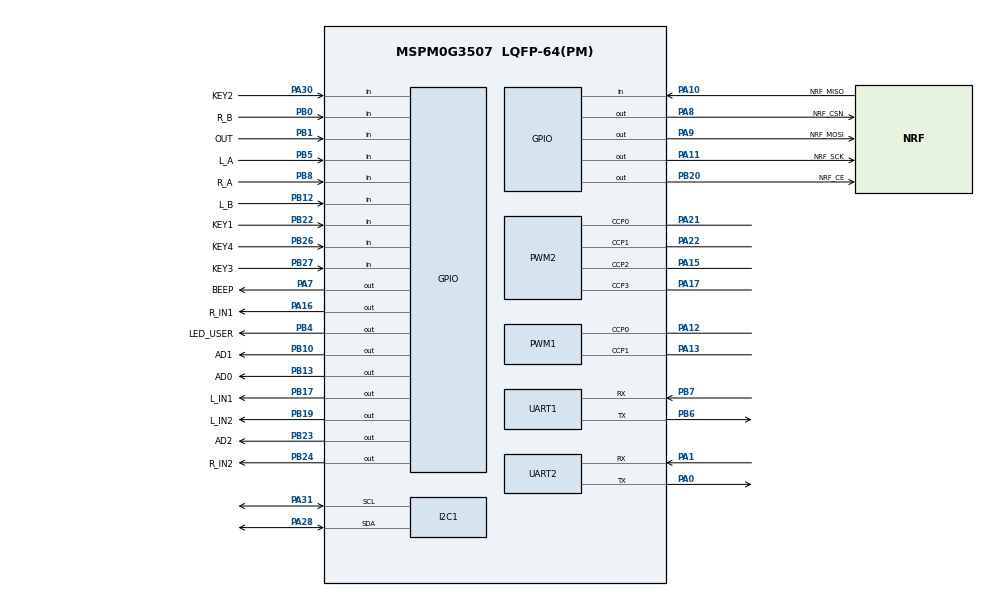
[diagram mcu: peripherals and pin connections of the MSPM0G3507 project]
/**
 * Revised local SysConfig script for the MSPM0G3507 slave car.
 *
 * MOTOR MIGRATION (2026-07): DC + TB6612 → Stepper + D36A.
 * - TB6612 L_IN1/L_IN2/R_IN1/R_IN2 GPIOs RETAINED as legacy output.
 *   PB17/PB19/PA16/PB24 are no longer used for DIR/EN.
 * - TIMG0 PWM_MOTOR PA12/PA13 RETAINED but unused at runtime.
 *
 * Stepper pins (initialized manually in StepperMotor.c):
 *   STEP_L = PB15 (TIMG7 CCP0, IOMUX_PINCM32 func6)
 *   STEP_R = PB16 (TIMG8 CCP1, IOMUX_PINCM33 func5)
 *   DIR_L  = PB18 (GPIO output, IOMUX_PINCM44)
 *   DIR_R  = PB25 (GPIO output, IOMUX_PINCM56)
 *   EN1/EN2 = hardware always enabled, no MCU GPIO.
 *
 * Encoder pins (initialized in Encoder.c):
 *   ENC_L_A = PB05 (IOMUX_PINCM18), ENC_L_B = PB12 (IOMUX_PINCM29)
 *   ENC_R_A = PB08 (IOMUX_PINCM25), ENC_R_B = PB00 (IOMUX_PINCM12)
 *   All on GPIOB, RISE_FALL interrupts, 4x quadrature.
 *
 * PB08 conflict: also H8 OLED SDA.  Set BOARD_OLED_USE_H8_I2C=0,
 * ECAR_OLED_ENABLE=0 when using stepper encoder.
 *
 * This file mirrors the checked-in ti_msp_dl_config.c/h logical names.
 * If SysConfig regenerates, keep App/Hardware code mapped through
 * Hardware/Board_Config.h.
 */
//@cliArgs --device "MSPM0G350X" --package "LQFP-64(PM)" --part "Default"
//@v2CliArgs --device "MSPM0G3507" --package "LQFP-64(PM)"
// @cliArgs --board /ti/boards/LP_MSPM0G3507 --rtos nortos

const GPIO   = scripting.addModule("/ti/driverlib/GPIO", {}, false);
const GPIO1  = GPIO.addInstance();
const GPIO2  = GPIO.addInstance();
const GPIO3  = GPIO.addInstance();
const GPIO4  = GPIO.addInstance();
const GPIO5  = GPIO.addInstance();
const GPIO_NRF = GPIO.addInstance();
const I2C    = scripting.addModule("/ti/driverlib/I2C", {}, false);
const I2C1   = I2C.addInstance();
const PWM    = scripting.addModule("/ti/driverlib/PWM", {}, false);
const PWM1   = PWM.addInstance();
const PWM2   = PWM.addInstance();
const TIMER  = scripting.addModule("/ti/driverlib/TIMER", {}, false);
const TIMER1 = TIMER.addInstance();
const UART   = scripting.addModule("/ti/driverlib/UART", {}, false);
const UART1  = UART.addInstance();
const SYSCTL = scripting.addModule("/ti/driverlib/SYSCTL");

const Board = scripting.addModule("/ti/driverlib/Board", {}, false);

/*
 * TB6612 motor GPIO (legacy, retained to keep SYSCFG_DL_GPIO_init stable):
 * L_IN1=PB17, L_IN2=PB19, R_IN1=PA16, R_IN2=PB24.
 * Not used in stepper mode.
 */
GPIO1.$name = "GPIO_MOTOR";
GPIO1.associatedPins.create(4);
GPIO1.associatedPins[0].$name        = "L_IN1";
GPIO1.associatedPins[0].assignedPort = "PORTB";
GPIO1.associatedPins[0].assignedPin  = "17";
GPIO1.associatedPins[0].pin.$assign  = "PB17";
GPIO1.associatedPins[0].initialValue = "CLEARED";
GPIO1.associatedPins[1].$name        = "L_IN2";
GPIO1.associatedPins[1].assignedPort = "PORTB";
GPIO1.associatedPins[1].assignedPin  = "19";
GPIO1.associatedPins[1].pin.$assign  = "PB19";
GPIO1.associatedPins[1].initialValue = "CLEARED";
GPIO1.associatedPins[2].$name        = "R_IN1";
GPIO1.associatedPins[2].assignedPort = "PORTA";
GPIO1.associatedPins[2].assignedPin  = "16";
GPIO1.associatedPins[2].pin.$assign  = "PA16";
GPIO1.associatedPins[2].initialValue = "CLEARED";
GPIO1.associatedPins[3].$name        = "R_IN2";
GPIO1.associatedPins[3].assignedPort = "PORTB";
GPIO1.associatedPins[3].assignedPin  = "24";
GPIO1.associatedPins[3].pin.$assign  = "PB24";
GPIO1.associatedPins[3].initialValue = "CLEARED";

/*
 * Encoder pins (GPIOB only, 4x quadrature).
 * Pin group kept as GPIO_ENCODER on PORTB for interrupt dispatch.
 * Actual pin init done in Encoder.c via Board_Config.h macros.
 */
GPIO2.$name = "GPIO_ENCODER";
GPIO2.associatedPins.create(4);
GPIO2.associatedPins[0].$name            = "L_A";
GPIO2.associatedPins[0].assignedPort     = "PORTB";
GPIO2.associatedPins[0].assignedPin      = "5";
GPIO2.associatedPins[0].pin.$assign      = "PB5";
GPIO2.associatedPins[0].direction        = "INPUT";
GPIO2.associatedPins[0].internalResistor = "PULL_UP";
GPIO2.associatedPins[0].inputFilter      = "8_CYCLES";
GPIO2.associatedPins[0].interruptEn      = true;
GPIO2.associatedPins[0].polarity         = "RISE_FALL";
GPIO2.associatedPins[1].$name            = "L_B";
GPIO2.associatedPins[1].assignedPort     = "PORTB";
GPIO2.associatedPins[1].assignedPin      = "12";
GPIO2.associatedPins[1].pin.$assign      = "PB12";
GPIO2.associatedPins[1].direction        = "INPUT";
GPIO2.associatedPins[1].internalResistor = "PULL_UP";
GPIO2.associatedPins[1].inputFilter      = "8_CYCLES";
GPIO2.associatedPins[1].interruptEn      = true;
GPIO2.associatedPins[1].polarity         = "RISE_FALL";
GPIO2.associatedPins[2].$name            = "R_A";
GPIO2.associatedPins[2].assignedPort     = "PORTB";
GPIO2.associatedPins[2].assignedPin      = "8";
GPIO2.associatedPins[2].pin.$assign      = "PB8";
GPIO2.associatedPins[2].direction        = "INPUT";
GPIO2.associatedPins[2].internalResistor = "PULL_UP";
GPIO2.associatedPins[2].inputFilter      = "8_CYCLES";
GPIO2.associatedPins[2].interruptEn      = true;
GPIO2.associatedPins[2].polarity         = "RISE_FALL";
GPIO2.associatedPins[3].$name            = "R_B";
GPIO2.associatedPins[3].assignedPort     = "PORTB";
GPIO2.associatedPins[3].assignedPin      = "0";
GPIO2.associatedPins[3].pin.$assign      = "PB0";
GPIO2.associatedPins[3].direction        = "INPUT";
GPIO2.associatedPins[3].internalResistor = "PULL_UP";
GPIO2.associatedPins[3].inputFilter      = "8_CYCLES";
GPIO2.associatedPins[3].interruptEn      = true;
GPIO2.associatedPins[3].polarity         = "RISE_FALL";

/*
 * 8-channel grayscale module.
 */
GPIO3.$name = "GPIO_GRAYSCALE";
GPIO3.associatedPins.create(4);
GPIO3.associatedPins[0].$name        = "AD2";
GPIO3.associatedPins[0].assignedPort = "PORTB";
GPIO3.associatedPins[0].assignedPin  = "23";
GPIO3.associatedPins[0].pin.$assign  = "PB23";
GPIO3.associatedPins[0].initialValue = "CLEARED";
GPIO3.associatedPins[1].$name        = "AD1";
GPIO3.associatedPins[1].assignedPort = "PORTB";
GPIO3.associatedPins[1].assignedPin  = "10";
GPIO3.associatedPins[1].pin.$assign  = "PB10";
GPIO3.associatedPins[1].initialValue = "CLEARED";
GPIO3.associatedPins[2].$name        = "AD0";
GPIO3.associatedPins[2].assignedPort = "PORTB";
GPIO3.associatedPins[2].assignedPin  = "13";
GPIO3.associatedPins[2].pin.$assign  = "PB13";
GPIO3.associatedPins[2].initialValue = "CLEARED";
GPIO3.associatedPins[3].$name            = "OUT";
GPIO3.associatedPins[3].assignedPort     = "PORTB";
GPIO3.associatedPins[3].assignedPin      = "1";
GPIO3.associatedPins[3].pin.$assign      = "PB1";
GPIO3.associatedPins[3].direction        = "INPUT";
GPIO3.associatedPins[3].internalResistor = "NONE";

GPIO4.$name = "GPIO_KEYS";
GPIO4.associatedPins.create(4);
GPIO4.associatedPins[0].$name            = "KEY1";
GPIO4.associatedPins[0].assignedPort     = "PORTB";
GPIO4.associatedPins[0].assignedPin      = "22";
GPIO4.associatedPins[0].pin.$assign      = "PB22";
GPIO4.associatedPins[0].direction        = "INPUT";
GPIO4.associatedPins[0].internalResistor = "PULL_UP";
GPIO4.associatedPins[1].$name            = "KEY2";
GPIO4.associatedPins[1].assignedPort     = "PORTA";
GPIO4.associatedPins[1].assignedPin      = "30";
GPIO4.associatedPins[1].pin.$assign      = "PA30";
GPIO4.associatedPins[1].direction        = "INPUT";
GPIO4.associatedPins[1].internalResistor = "PULL_UP";
GPIO4.associatedPins[2].$name            = "KEY3";
GPIO4.associatedPins[2].assignedPort     = "PORTB";
GPIO4.associatedPins[2].assignedPin      = "27";
GPIO4.associatedPins[2].pin.$assign      = "PB27";
GPIO4.associatedPins[2].direction        = "INPUT";
GPIO4.associatedPins[2].internalResistor = "PULL_UP";
GPIO4.associatedPins[3].$name            = "KEY4";
GPIO4.associatedPins[3].assignedPort     = "PORTB";
GPIO4.associatedPins[3].assignedPin      = "26";
GPIO4.associatedPins[3].pin.$assign      = "PB26";
GPIO4.associatedPins[3].direction        = "INPUT";
GPIO4.associatedPins[3].internalResistor = "PULL_UP";

GPIO5.$name = "GPIO_BOARD_IO";
GPIO5.associatedPins.create(2);
GPIO5.associatedPins[0].$name        = "LED_USER";
GPIO5.associatedPins[0].assignedPort = "PORTB";
GPIO5.associatedPins[0].assignedPin  = "4";
GPIO5.associatedPins[0].pin.$assign  = "PB4";
GPIO5.associatedPins[0].initialValue = "CLEARED";
GPIO5.associatedPins[1].$name        = "BEEP";
GPIO5.associatedPins[1].assignedPort = "PORTA";
GPIO5.associatedPins[1].assignedPin  = "7";
GPIO5.associatedPins[1].pin.$assign  = "PA7";
GPIO5.associatedPins[1].initialValue = "CLEARED";

PWM1.$name                      = "PWM_MOTOR";
PWM1.timerCount                 = 1600;
PWM1.peripheral.$assign         = "TIMG0";
PWM1.peripheral.ccp0Pin.$assign = "PA12";
PWM1.peripheral.ccp1Pin.$assign = "PA13";
PWM1.PWM_CHANNEL_0.$name        = "MOTOR_C0";
PWM1.PWM_CHANNEL_0.dutyCycle    = 0;
PWM1.PWM_CHANNEL_1.$name        = "MOTOR_C1";
PWM1.PWM_CHANNEL_1.dutyCycle    = 0;

PWM2.$name                      = "PWM_SERVO";
PWM2.ccIndex                    = [0,1,2,3];
PWM2.clockPrescale              = 32;
PWM2.timerCount                 = 20000;
PWM2.peripheral.$assign         = "TIMA0";
PWM2.peripheral.ccp0Pin.$assign = "PA21";
PWM2.peripheral.ccp1Pin.$assign = "PA22";
PWM2.peripheral.ccp2Pin.$assign = "PA15";
PWM2.peripheral.ccp3Pin.$assign = "PA17";
PWM2.PWM_CHANNEL_0.$name        = "SERVO_C0";
PWM2.PWM_CHANNEL_0.dutyCycle    = 0;
PWM2.PWM_CHANNEL_1.$name        = "SERVO_C1";
PWM2.PWM_CHANNEL_1.dutyCycle    = 0;
PWM2.PWM_CHANNEL_2.$name        = "SERVO_C2";
PWM2.PWM_CHANNEL_2.dutyCycle    = 0;
PWM2.PWM_CHANNEL_3.$name        = "SERVO_C3";
PWM2.PWM_CHANNEL_3.dutyCycle    = 0;

TIMER1.$name              = "TIMER_SYS";
TIMER1.profile            = "Basic_Periodic";
TIMER1.timerPeriod        = "1 ms";
TIMER1.peripheral.$assign = "TIMG6";

UART1.$name                    = "UART_DEBUG";
UART1.profile                  = "CONFIG_PROFILE_1";
UART1.peripheral.$assign       = "UART1";
UART1.targetBaudRate           = 9600;
UART1.enableInternalLoopback   = false;
UART1.enableFIFO              = false;
UART1.enabledInterrupts        = ["RX"];
UART1.peripheral.txPin.$assign = "PB6";
UART1.peripheral.rxPin.$assign = "PB7";

const UART2  = UART.addInstance();
UART2.$name                    = "UART_K230";
UART2.profile                  = "CONFIG_PROFILE_1";
UART2.peripheral.$assign       = "UART0";
UART2.targetBaudRate           = 115200;
UART2.enableInternalLoopback   = false;
UART2.enableFIFO              = false;
UART2.enabledInterrupts        = ["RX"];
UART2.peripheral.txPin.$assign = "PA0";
UART2.peripheral.rxPin.$assign = "PA1";

I2C1.$name                     = "I2C_SHARED";
I2C1.basicEnableController     = true;
I2C1.basicControllerBusSpeed   = 100000;
I2C1.advAnalogGlitchFilter     = "DISABLED";
I2C1.peripheral.$assign        = "I2C0";
I2C1.peripheral.sclPin.$assign = "PA31";
I2C1.peripheral.sdaPin.$assign = "PA28";

GPIO_NRF.$name = "GPIO_NRF";
GPIO_NRF.associatedPins.create(5);
GPIO_NRF.associatedPins[0].$name            = "NRF_CE";
GPIO_NRF.associatedPins[0].assignedPort     = "PORTB";
GPIO_NRF.associatedPins[0].assignedPin      = "20";
GPIO_NRF.associatedPins[0].pin.$assign      = "PB20";
GPIO_NRF.associatedPins[0].direction        = "OUTPUT";
GPIO_NRF.associatedPins[0].initialValue     = "CLEARED";
GPIO_NRF.associatedPins[1].$name            = "NRF_CSN";
GPIO_NRF.associatedPins[1].assignedPort     = "PORTA";
GPIO_NRF.associatedPins[1].assignedPin      = "8";
GPIO_NRF.associatedPins[1].pin.$assign      = "PA8";
GPIO_NRF.associatedPins[1].direction        = "OUTPUT";
GPIO_NRF.associatedPins[1].initialValue     = "SET";
GPIO_NRF.associatedPins[2].$name            = "NRF_SCK";
GPIO_NRF.associatedPins[2].assignedPort     = "PORTA";
GPIO_NRF.associatedPins[2].assignedPin      = "11";
GPIO_NRF.associatedPins[2].pin.$assign      = "PA11";
GPIO_NRF.associatedPins[2].direction        = "OUTPUT";
GPIO_NRF.associatedPins[2].initialValue     = "CLEARED";
GPIO_NRF.associatedPins[3].$name            = "NRF_MOSI";
GPIO_NRF.associatedPins[3].assignedPort     = "PORTA";
GPIO_NRF.associatedPins[3].assignedPin      = "9";
GPIO_NRF.associatedPins[3].pin.$assign      = "PA9";
GPIO_NRF.associatedPins[3].direction        = "OUTPUT";
GPIO_NRF.associatedPins[3].initialValue     = "CLEARED";
GPIO_NRF.associatedPins[4].$name            = "NRF_MISO";
GPIO_NRF.associatedPins[4].assignedPort     = "PORTA";
GPIO_NRF.associatedPins[4].assignedPin      = "10";
GPIO_NRF.associatedPins[4].pin.$assign      = "PA10";
GPIO_NRF.associatedPins[4].direction        = "INPUT";
GPIO_NRF.associatedPins[4].internalResistor = "NONE";

SYSCTL.forceDefaultClkConfig = true;
SYSCTL.clockTreeEn = true;
